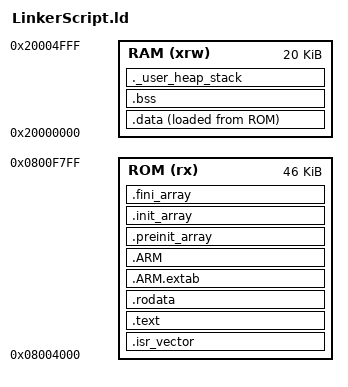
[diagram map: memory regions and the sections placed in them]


/* Entry Point */
ENTRY(Reset_Handler)

/* Highest address of the user mode stack */
_estack = 0x20005000;    /* end of RAM */

_Min_Heap_Size = 0x300;      /* required amount of heap  */
_Min_Stack_Size = 1024; /* required amount of stack */

/* Memories definition */
MEMORY
{
  RAM (xrw)		: ORIGIN = 0x20000000, LENGTH = 20K
 /* LOCAL_BUILD*/
/*ROM (rx)		: ORIGIN = 0x08000000, LENGTH = 46K*/
  /* production*/
ROM (rx)		: ORIGIN = 0x08004000, LENGTH = 46K
  
  
  
}
/* ROM is normally 48K after the bootloader, however we allocate the last page for settings, and the second last one for display boot logo*/

/* Sections */
SECTIONS
{
  /* The startup code into ROM memory */
  .isr_vector :
  {
    . = ALIGN(4);
    KEEP(*(.isr_vector)) /* Startup code */
    . = ALIGN(4);
  } >ROM

  /* The program code and other data into ROM memory */
  .text :
  {
    . = ALIGN(4);
    *(.text)           /* .text sections (code) */
    *(.text*)          /* .text* sections (code) */
    *(.glue_7)         /* glue arm to thumb code */
    *(.glue_7t)        /* glue thumb to arm code */
    *(.eh_frame)

    KEEP (*(.init))
    KEEP (*(.fini))

    . = ALIGN(4);
    _etext = .;        /* define a global symbols at end of code */
  } >ROM

  /* Constant data into ROM memory*/
  .rodata :
  {
    . = ALIGN(4);
    *(.rodata)         /* .rodata sections (constants, strings, etc.) */
    *(.rodata*)        /* .rodata* sections (constants, strings, etc.) */
    . = ALIGN(4);
  } >ROM

  .ARM.extab   : { 
  	. = ALIGN(4);
  	*(.ARM.extab* .gnu.linkonce.armextab.*)
  	. = ALIGN(4);
  } >ROM
  
  .ARM : {
    . = ALIGN(4);
    __exidx_start = .;
    *(.ARM.exidx*)
    __exidx_end = .;
    . = ALIGN(4);
  } >ROM

  .preinit_array     :
  {
    . = ALIGN(4);
    PROVIDE_HIDDEN (__preinit_array_start = .);
    KEEP (*(.preinit_array*))
    PROVIDE_HIDDEN (__preinit_array_end = .);
    . = ALIGN(4);
  } >ROM
  
  .init_array :
  {
    . = ALIGN(4);
    PROVIDE_HIDDEN (__init_array_start = .);
    KEEP (*(SORT(.init_array.*)))
    KEEP (*(.init_array*))
    PROVIDE_HIDDEN (__init_array_end = .);
    . = ALIGN(4);
  } >ROM
  
  .fini_array :
  {
    . = ALIGN(4);
    PROVIDE_HIDDEN (__fini_array_start = .);
    KEEP (*(SORT(.fini_array.*)))
    KEEP (*(.fini_array*))
    PROVIDE_HIDDEN (__fini_array_end = .);
    . = ALIGN(4);
  } >ROM

  /* Used by the startup to initialize data */
  _sidata = LOADADDR(.data);

  /* Initialized data sections into RAM memory */
  .data : 
  {
    . = ALIGN(4);
    _sdata = .;        /* create a global symbol at data start */
    *(.data)           /* .data sections */
    *(.data*)          /* .data* sections */

    . = ALIGN(4);
    _edata = .;        /* define a global symbol at data end */
  } >RAM AT> ROM

  
  /* Uninitialized data section into RAM memory */
  . = ALIGN(4);
  .bss :
  {
    /* This is used by the startup in order to initialize the .bss secion */
    _sbss = .;         /* define a global symbol at bss start */
    __bss_start__ = _sbss;
    *(.bss)
    *(.bss*)
    *(COMMON)

    . = ALIGN(4);
    _ebss = .;         /* define a global symbol at bss end */
    __bss_end__ = _ebss;
  } >RAM

  /* User_heap_stack section, used to check that there is enough RAM left */
  ._user_heap_stack :
  {
    . = ALIGN(8);
    PROVIDE ( end = . );
    PROVIDE ( _end = . );
    . = . + _Min_Heap_Size;
    . = . + _Min_Stack_Size;
    . = ALIGN(8);
  } >RAM

  

  /* Remove information from the compiler libraries */
  /DISCARD/ :
  {
    libc.a ( * )
    libm.a ( * )
    libgcc.a ( * )
  }

  .ARM.attributes 0 : { *(.ARM.attributes) }
}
